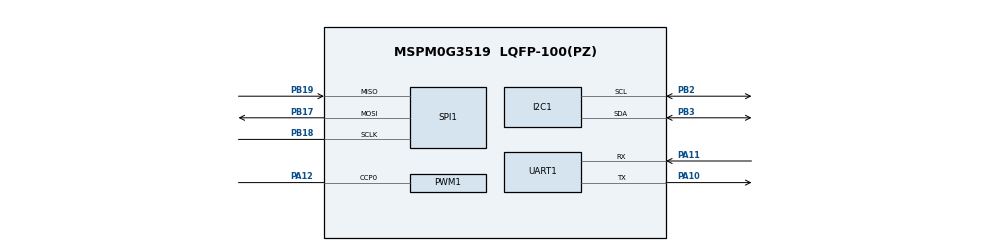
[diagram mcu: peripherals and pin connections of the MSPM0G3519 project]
/**
 * These arguments were used when this file was generated. They will be automatically applied on subsequent loads
 * via the GUI or CLI. Run CLI with '--help' for additional information on how to override these arguments.
 * @cliArgs --device "MSPM0G351X" --part "Default" --package "LQFP-100(PZ)" --product "mspm0_sdk@2.10.00.04"
 * @v2CliArgs --device "MSPM0G3519" --package "LQFP-100(PZ)" --product "mspm0_sdk@2.10.00.04"
 * @versions {"tool":"1.26.2+4477"}
 */

/**
 * Import the modules used in this configuration.
 */
const GPIO   = scripting.addModule("/ti/driverlib/GPIO", {}, false);
const GPIO1  = GPIO.addInstance();
const GPIO2  = GPIO.addInstance();
const GPIO3  = GPIO.addInstance();
const GPIO4  = GPIO.addInstance();
const GPIO5  = GPIO.addInstance();
const GPIO6  = GPIO.addInstance();
const GPIO7  = GPIO.addInstance();
const GPIO8  = GPIO.addInstance();
const GPIO9  = GPIO.addInstance();
const GPIO10 = GPIO.addInstance();
const GPIO11 = GPIO.addInstance();
const I2C    = scripting.addModule("/ti/driverlib/I2C", {}, false);
const I2C1   = I2C.addInstance();
const PWM    = scripting.addModule("/ti/driverlib/PWM", {}, false);
const PWM1   = PWM.addInstance();
const SPI    = scripting.addModule("/ti/driverlib/SPI", {}, false);
const SPI1   = SPI.addInstance();
const SPI2   = SPI.addInstance();
const SPI3   = SPI.addInstance();
const SYSCTL = scripting.addModule("/ti/driverlib/SYSCTL");
const TIMER  = scripting.addModule("/ti/driverlib/TIMER", {}, false);
const TIMER1 = TIMER.addInstance();
const TIMER2 = TIMER.addInstance();
const UART   = scripting.addModule("/ti/driverlib/UART", {}, false);
const UART1  = UART.addInstance();

/**
 * Write custom configuration values to the imported modules.
 */
GPIO1.$name                                 = "BATTERY_CS";
GPIO1.associatedPins[0].$name               = "CS1";
GPIO1.associatedPins[0].initialValue        = "SET";
GPIO1.associatedPins[0].assignedPort        = "PORTA";
GPIO1.associatedPins[0].assignedPortSegment = "Lower";
GPIO1.associatedPins[0].assignedPin         = "8";

const Board = scripting.addModule("/ti/driverlib/Board", {}, false);

GPIO2.$name                                 = "SELECT_CONVERTER";
GPIO2.associatedPins[0].internalResistor    = "PULL_DOWN";
GPIO2.associatedPins[0].$name               = "PIN_0";
GPIO2.associatedPins[0].direction           = "INPUT";
GPIO2.associatedPins[0].assignedPort        = "PORTB";
GPIO2.associatedPins[0].assignedPortSegment = "Lower";
GPIO2.associatedPins[0].assignedPin         = "1";

GPIO3.$name                                 = "RECT_CS";
GPIO3.associatedPins[0].$name               = "CS2";
GPIO3.associatedPins[0].initialValue        = "SET";
GPIO3.associatedPins[0].assignedPort        = "PORTA";
GPIO3.associatedPins[0].assignedPortSegment = "Upper";
GPIO3.associatedPins[0].assignedPin         = "31";

GPIO4.$name                                 = "BAT_ALERT";
GPIO4.associatedPins[0].$name               = "PIN_1";
GPIO4.associatedPins[0].direction           = "INPUT";
GPIO4.associatedPins[0].ioStructure         = "SD";
GPIO4.associatedPins[0].assignedPort        = "PORTB";
GPIO4.associatedPins[0].assignedPin         = "13";
GPIO4.associatedPins[0].assignedPortSegment = "Lower";
GPIO4.associatedPins[0].interruptEn         = true;
GPIO4.associatedPins[0].polarity            = "FALL";
GPIO4.associatedPins[0].internalResistor    = "PULL_UP";

GPIO5.$name                              = "RECT_ALERT";
GPIO5.associatedPins[0].$name            = "PIN_2";
GPIO5.associatedPins[0].direction        = "INPUT";
GPIO5.associatedPins[0].ioStructure      = "SD";
GPIO5.associatedPins[0].interruptEn      = true;
GPIO5.associatedPins[0].polarity         = "FALL";
GPIO5.associatedPins[0].internalResistor = "PULL_UP";

GPIO6.$name                           = "BATTERY_RELAY";
GPIO6.associatedPins[0].driveStrength = "HIGH";
GPIO6.associatedPins[0].ioStructure   = "HD";
GPIO6.associatedPins[0].$name         = "IN1";

GPIO7.$name                   = "DUMP_LOAD_RELAY";
GPIO7.associatedPins[0].$name = "IN2";

GPIO8.$name                   = "LCD";
GPIO8.associatedPins.create(6);
GPIO8.associatedPins[0].$name = "RS";
GPIO8.associatedPins[1].$name = "EN";
GPIO8.associatedPins[2].$name = "D4";
GPIO8.associatedPins[3].$name = "D5";
GPIO8.associatedPins[4].$name = "D6";
GPIO8.associatedPins[5].$name = "D7";

GPIO9.$name                              = "UI_BUTTON";
GPIO9.associatedPins.create(4);
GPIO9.associatedPins[0].$name            = "NEXT";
GPIO9.associatedPins[0].direction        = "INPUT";
GPIO9.associatedPins[0].internalResistor = "PULL_DOWN";
GPIO9.associatedPins[0].interruptEn      = true;
GPIO9.associatedPins[0].polarity         = "RISE";
GPIO9.associatedPins[1].$name            = "PREV";
GPIO9.associatedPins[1].direction        = "INPUT";
GPIO9.associatedPins[1].internalResistor = "PULL_DOWN";
GPIO9.associatedPins[1].interruptEn      = true;
GPIO9.associatedPins[1].polarity         = "RISE";
GPIO9.associatedPins[2].internalResistor = "PULL_DOWN";
GPIO9.associatedPins[2].$name            = "START_STOP";
GPIO9.associatedPins[2].direction        = "INPUT";
GPIO9.associatedPins[2].interruptEn      = true;
GPIO9.associatedPins[2].polarity         = "RISE";
GPIO9.associatedPins[3].$name            = "RECORD";
GPIO9.associatedPins[3].direction        = "INPUT";
GPIO9.associatedPins[3].internalResistor = "PULL_DOWN";
GPIO9.associatedPins[3].interruptEn      = true;
GPIO9.associatedPins[3].polarity         = "RISE";

GPIO10.$name                   = "UI_LED";
GPIO10.associatedPins.create(5);
GPIO10.associatedPins[0].$name = "START";
GPIO10.associatedPins[1].$name = "STOP";
GPIO10.associatedPins[2].$name = "IS_RECORDING";
GPIO10.associatedPins[3].$name = "TURBINE_OK";
GPIO10.associatedPins[4].$name = "LOAD_UI_OK";

GPIO11.$name                          = "SD_CS";
GPIO11.associatedPins[0].$name        = "CS";
GPIO11.associatedPins[0].initialValue = "SET";

I2C1.$name                             = "MCP45HV51";
I2C1.basicEnableController             = true;
I2C1.basicControllerBusSpeed           = 400000;
I2C1.advAnalogGlitchFilter             = "DISABLED";
I2C1.peripheral.$assign                = "I2C1";
I2C1.peripheral.sdaPin.$assign         = "PB3";
I2C1.peripheral.sclPin.$assign         = "PB2";
I2C1.sdaPinConfig.hideOutputInversion  = scripting.forceWrite(false);
I2C1.sdaPinConfig.onlyInternalResistor = scripting.forceWrite(false);
I2C1.sdaPinConfig.passedPeripheralType = scripting.forceWrite("Digital");
I2C1.sdaPinConfig.$name                = "ti_driverlib_gpio_GPIOPinGeneric6";
I2C1.sdaPinConfig.enableConfig         = true;
I2C1.sdaPinConfig.internalResistor     = "PULL_UP";
I2C1.sclPinConfig.hideOutputInversion  = scripting.forceWrite(false);
I2C1.sclPinConfig.onlyInternalResistor = scripting.forceWrite(false);
I2C1.sclPinConfig.passedPeripheralType = scripting.forceWrite("Digital");
I2C1.sclPinConfig.$name                = "ti_driverlib_gpio_GPIOPinGeneric7";
I2C1.sclPinConfig.enableConfig         = true;
I2C1.sclPinConfig.internalResistor     = "PULL_UP";

PWM1.$name                      = "PWM_0";
PWM1.timerCount                 = 320;
PWM1.ccIndex                    = [0];
PWM1.pwmMode                    = "EDGE_ALIGN_UP";
PWM1.PWM_CHANNEL_0.$name        = "ti_driverlib_pwm_PWMTimerCC0";
PWM1.PWM_CHANNEL_0.dutyCycle    = 30;
PWM1.ccp0PinConfig.$name        = "ti_driverlib_gpio_GPIOPinGeneric5";
PWM1.peripheral.ccp0Pin.$assign = "PA12";

SPI1.enableDMAEvent1                    = false;
SPI1.enableDMAEvent2                    = false;
SPI1.spiClkSrc                          = "MFCLK";
SPI1.spiClkDiv                          = "4";
SPI1.frameFormat                        = "MOTO3";
SPI1.chipSelect                         = [];
SPI1.phase                              = "1";
SPI1.targetBitRate                      = 500000;
SPI1.rxFifoThreshold                    = "DL_SPI_RX_FIFO_LEVEL_ONE_FRAME";
SPI1.txFifoThreshold                    = "DL_SPI_TX_FIFO_LEVEL_ONE_FRAME";
SPI1.$name                              = "INA229_BATTERY_SPI0";
SPI1.sclkPinConfig.direction            = scripting.forceWrite("OUTPUT");
SPI1.sclkPinConfig.onlyInternalResistor = scripting.forceWrite(false);
SPI1.sclkPinConfig.passedPeripheralType = scripting.forceWrite("Digital");
SPI1.sclkPinConfig.$name                = "ti_driverlib_gpio_GPIOPinGeneric0";
SPI1.mosiPinConfig.direction            = scripting.forceWrite("OUTPUT");
SPI1.mosiPinConfig.hideOutputInversion  = scripting.forceWrite(false);
SPI1.mosiPinConfig.onlyInternalResistor = scripting.forceWrite(false);
SPI1.mosiPinConfig.passedPeripheralType = scripting.forceWrite("Digital");
SPI1.mosiPinConfig.$name                = "ti_driverlib_gpio_GPIOPinGeneric1";
SPI1.misoPinConfig.onlyInternalResistor = scripting.forceWrite(false);
SPI1.misoPinConfig.passedPeripheralType = scripting.forceWrite("Digital");
SPI1.misoPinConfig.$name                = "ti_driverlib_gpio_GPIOPinGeneric2";
SPI1.peripheral.$assign                 = "SPI0";
SPI1.peripheral.sclkPin.$assign         = "PB18";
SPI1.peripheral.mosiPin.$assign         = "PB17";
SPI1.peripheral.misoPin.$assign         = "PB19";

SPI2.targetBitRate                      = 500000;
SPI2.frameFormat                        = "MOTO3";
SPI2.phase                              = "1";
SPI2.rxFifoThreshold                    = "DL_SPI_RX_FIFO_LEVEL_ONE_FRAME";
SPI2.txFifoThreshold                    = "DL_SPI_TX_FIFO_LEVEL_ONE_FRAME";
SPI2.$name                              = "INA229_RECT_SPI1";
SPI2.sclkPinConfig.$name                = "ti_driverlib_gpio_GPIOPinGeneric8";
SPI2.sclkPinConfig.direction            = scripting.forceWrite("OUTPUT");
SPI2.sclkPinConfig.onlyInternalResistor = scripting.forceWrite(false);
SPI2.sclkPinConfig.passedPeripheralType = scripting.forceWrite("Digital");
SPI2.mosiPinConfig.$name                = "ti_driverlib_gpio_GPIOPinGeneric9";
SPI2.mosiPinConfig.direction            = scripting.forceWrite("OUTPUT");
SPI2.mosiPinConfig.hideOutputInversion  = scripting.forceWrite(false);
SPI2.mosiPinConfig.onlyInternalResistor = scripting.forceWrite(false);
SPI2.mosiPinConfig.passedPeripheralType = scripting.forceWrite("Digital");
SPI2.misoPinConfig.$name                = "ti_driverlib_gpio_GPIOPinGeneric10";
SPI2.misoPinConfig.onlyInternalResistor = scripting.forceWrite(false);
SPI2.misoPinConfig.passedPeripheralType = scripting.forceWrite("Digital");

SPI3.frameFormat                        = "MOTO3";
SPI3.chipSelect                         = [];
SPI3.enableDMAEvent1                    = false;
SPI3.enableDMAEvent2                    = false;
SPI3.$name                              = "SD_CARD_SPI_2";
SPI3.sclkPinConfig.direction            = scripting.forceWrite("OUTPUT");
SPI3.sclkPinConfig.onlyInternalResistor = scripting.forceWrite(false);
SPI3.sclkPinConfig.passedPeripheralType = scripting.forceWrite("Digital");
SPI3.sclkPinConfig.$name                = "ti_driverlib_gpio_GPIOPinGeneric11";
SPI3.mosiPinConfig.direction            = scripting.forceWrite("OUTPUT");
SPI3.mosiPinConfig.hideOutputInversion  = scripting.forceWrite(false);
SPI3.mosiPinConfig.onlyInternalResistor = scripting.forceWrite(false);
SPI3.mosiPinConfig.passedPeripheralType = scripting.forceWrite("Digital");
SPI3.mosiPinConfig.$name                = "ti_driverlib_gpio_GPIOPinGeneric12";
SPI3.misoPinConfig.onlyInternalResistor = scripting.forceWrite(false);
SPI3.misoPinConfig.passedPeripheralType = scripting.forceWrite("Digital");
SPI3.misoPinConfig.$name                = "ti_driverlib_gpio_GPIOPinGeneric13";

SYSCTL.forceDefaultClkConfig = true;
SYSCTL.MFCLKEn               = true;

TIMER1.timerClkSrc        = "LFCLK";
TIMER1.timerMode          = "PERIODIC_UP";
TIMER1.timerStartTimer    = true;
TIMER1.interrupts         = ["ZERO"];
TIMER1.timerPeriod        = "50 ms";
TIMER1.$name              = "CONVERTERS_TIMER";
TIMER1.peripheral.$assign = "TIMA0";

TIMER2.timerClkSrc        = "LFCLK";
TIMER2.timerMode          = "PERIODIC_UP";
TIMER2.timerStartTimer    = true;
TIMER2.timerPeriod        = "2 s";
TIMER2.$name              = "UART_TIMER";
TIMER2.interrupts         = ["ZERO"];
TIMER2.peripheral.$assign = "TIMA1";

UART1.$name                    = "UART_0";
UART1.enableFIFO               = true;
UART1.rxFifoThreshold          = "DL_UART_RX_FIFO_LEVEL_ONE_ENTRY";
UART1.enableDMARX              = false;
UART1.enableDMATX              = false;
UART1.peripheral.$assign       = "UART0";
UART1.peripheral.rxPin.$assign = "PA11";
UART1.peripheral.txPin.$assign = "PA10";
UART1.txPinConfig.$name        = "ti_driverlib_gpio_GPIOPinGeneric3";
UART1.rxPinConfig.$name        = "ti_driverlib_gpio_GPIOPinGeneric4";

const ProjectConfig              = scripting.addModule("/ti/project_config/ProjectConfig", {}, false);
ProjectConfig.migrationCondition = true;

/**
 * Pinmux solution for unlocked pins/peripherals. This ensures that minor changes to the automatic solver in a future
 * version of the tool will not impact the pinmux you originally saw.  These lines can be completely deleted in order to
 * re-solve from scratch.
 */
GPIO1.associatedPins[0].pin.$suggestSolution  = "PA8";
Board.peripheral.$suggestSolution             = "DEBUGSS";
Board.peripheral.swclkPin.$suggestSolution    = "PA20";
Board.peripheral.swdioPin.$suggestSolution    = "PA19";
GPIO2.associatedPins[0].pin.$suggestSolution  = "PB1";
GPIO3.associatedPins[0].pin.$suggestSolution  = "PA31";
GPIO4.associatedPins[0].pin.$suggestSolution  = "PB13";
GPIO5.associatedPins[0].pin.$suggestSolution  = "PA29";
GPIO6.associatedPins[0].pin.$suggestSolution  = "PA28";
GPIO7.associatedPins[0].pin.$suggestSolution  = "PA0";
GPIO8.associatedPins[0].pin.$suggestSolution  = "PA30";
GPIO8.associatedPins[1].pin.$suggestSolution  = "PC12";
GPIO8.associatedPins[2].pin.$suggestSolution  = "PC15";
GPIO8.associatedPins[3].pin.$suggestSolution  = "PC13";
GPIO8.associatedPins[4].pin.$suggestSolution  = "PC28";
GPIO8.associatedPins[5].pin.$suggestSolution  = "PA3";
GPIO9.associatedPins[0].pin.$suggestSolution  = "PA4";
GPIO9.associatedPins[1].pin.$suggestSolution  = "PA5";
GPIO9.associatedPins[2].pin.$suggestSolution  = "PA6";
GPIO9.associatedPins[3].pin.$suggestSolution  = "PB0";
GPIO10.associatedPins[0].pin.$suggestSolution = "PA7";
GPIO10.associatedPins[1].pin.$suggestSolution = "PB5";
GPIO10.associatedPins[2].pin.$suggestSolution = "PA9";
GPIO10.associatedPins[3].pin.$suggestSolution = "PB28";
GPIO10.associatedPins[4].pin.$suggestSolution = "PB29";
GPIO11.associatedPins[0].pin.$suggestSolution = "PA1";
PWM1.peripheral.$suggestSolution              = "TIMG0";
SPI2.peripheral.$suggestSolution              = "SPI2";
SPI2.peripheral.sclkPin.$suggestSolution      = "PC14";
SPI2.peripheral.mosiPin.$suggestSolution      = "PB4";
SPI2.peripheral.misoPin.$suggestSolution      = "PA2";
SPI3.peripheral.$suggestSolution              = "SPI1";
SPI3.peripheral.sclkPin.$suggestSolution      = "PA17";
SPI3.peripheral.mosiPin.$suggestSolution      = "PA18";
SPI3.peripheral.misoPin.$suggestSolution      = "PA16";
SYSCTL.peripheral.$suggestSolution            = "SYSCTL";
